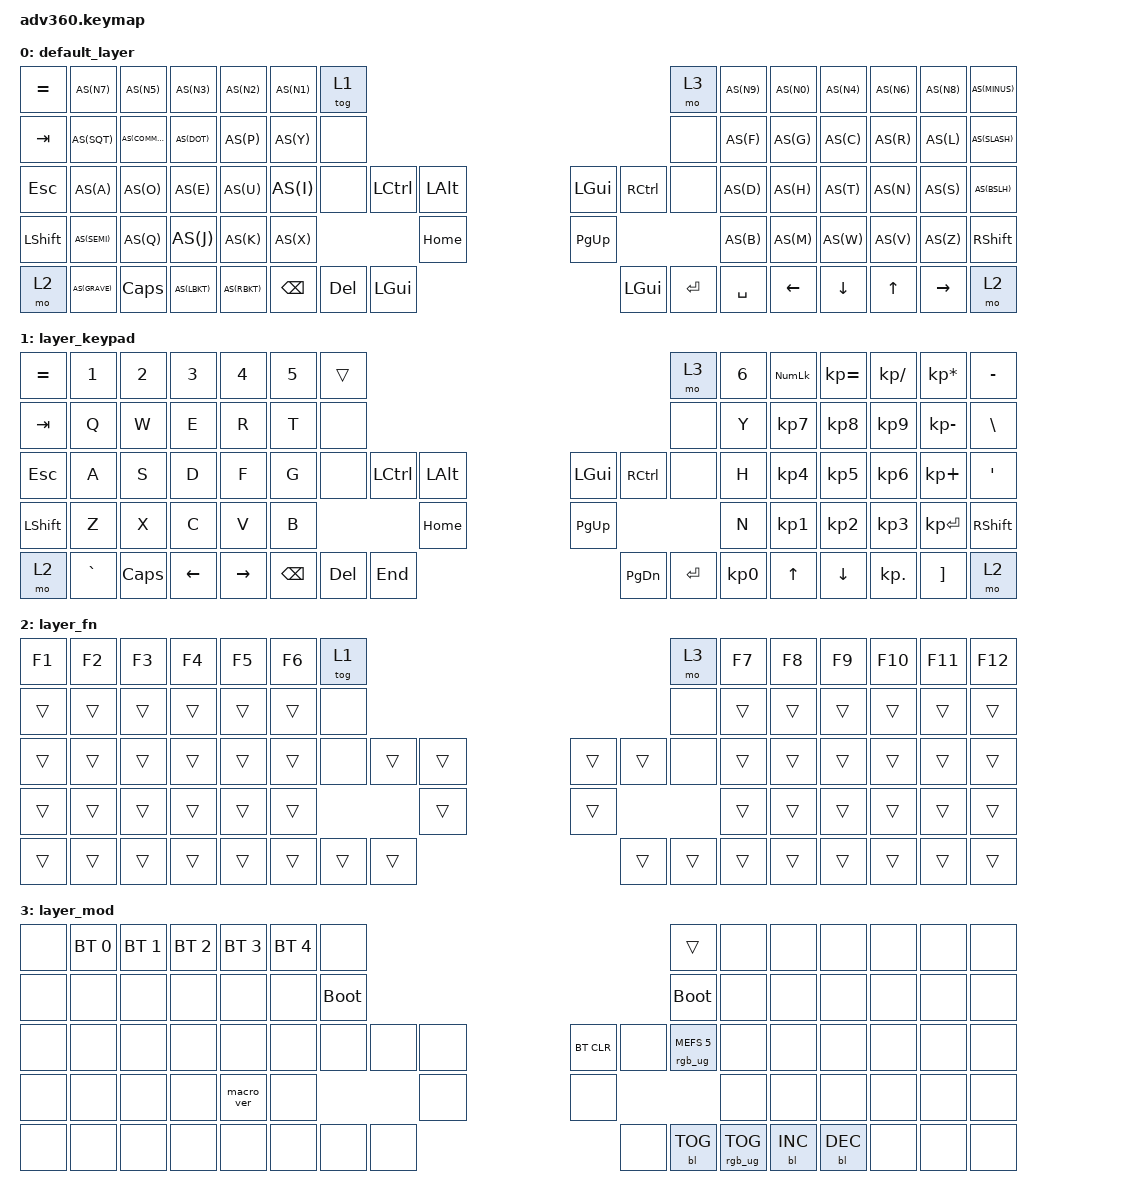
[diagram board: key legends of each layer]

/*
 * Copyright (c) 2020 The ZMK Contributors
 *
 * SPDX-License-Identifier: MIT
 */


/* THIS FILE WAS GENERATED!
 *
 * This file was generated automatically. You may or may not want to
 * edit it directly.
 */

#include <behaviors.dtsi>
#include <dt-bindings/zmk/keys.h>
#include <dt-bindings/zmk/bt.h>
#include <dt-bindings/zmk/rgb.h>
#include <dt-bindings/zmk/backlight.h>

#define AS(keycode) &as LS(keycode) keycode     // Autoshift Macro

/ {
  behaviors {
    #include "macros.dtsi"
    #include "version.dtsi"

    hm: homerow_mods {
        compatible = "zmk,behavior-hold-tap";
        label = "HOMEROW_MODS";
        #binding-cells = <2>;
        tapping-term-ms = <200>;
        quick_tap_ms = <175>;
        flavor = "tap-preferred";
        bindings = <&kp>, <&kp>;
    };

    as: auto_shift {
        compatible = "zmk,behavior-hold-tap";
        #binding-cells = <2>;
        tapping_term_ms = <250>;
        quick_tap_ms = <0>;
        flavor = "tap-preferred";
        bindings = <&kp>, <&kp>;
    };
  };

    keymap {
        compatible = "zmk,keymap";


        default_layer {
            bindings = <
 &kp EQUAL      AS(N7)     AS(N5)    AS(N3)    AS(N2)   AS(N1)             &tog 1                                                                 &mo 3   AS(N9)    AS(N0)    AS(N4)  AS(N6)     AS(N8)  AS(MINUS)
   &kp TAB     AS(SQT)  AS(COMMA)   AS(DOT)     AS(P)    AS(Y)              &none                                                                 &none    AS(F)     AS(G)     AS(C)   AS(R)      AS(L)  AS(SLASH)
   &kp ESC       AS(A)      AS(O)     AS(E)     AS(U)    AS(I)              &none  &kp LCTRL  &kp LALT                   &kp LGUI  &kp RCTRL      &none    AS(D)     AS(H)     AS(T)   AS(N)      AS(S)   AS(BSLH)
 &kp LSHFT    AS(SEMI)      AS(Q)     AS(J)     AS(K)    AS(X)                                &kp HOME                  &kp PG_UP                          AS(B)     AS(M)     AS(W)   AS(V)      AS(Z) &kp RSHFT
     &mo 2   AS(GRAVE)  &kp CAPS   AS(LBKT)  AS(RBKT)                   &kp BSPC    &kp DEL   &kp LGUI                  &kp LGUI   &kp ENTER  &kp SPACE          &kp LEFT  &kp DOWN  &kp UP  &kp RIGHT      &mo 2
            >;
        };

        layer_keypad {
            bindings = <
 &kp EQUAL     &kp N1    &kp N2    &kp N3     &kp N4  &kp N5              &trans                                                                 &mo 3  &kp N6  &kp KP_NUM  &kp KP_EQUAL  &kp KP_DIVIDE  &kp KP_MULTIPLY  &kp MINUS
   &kp TAB      &kp Q     &kp W     &kp E      &kp R   &kp T               &none                                                                 &none   &kp Y   &kp KP_N7     &kp KP_N8      &kp KP_N9     &kp KP_MINUS   &kp BSLH
   &kp ESC      &kp A     &kp S     &kp D      &kp F   &kp G               &none  &kp LCTRL  &kp LALT                   &kp LGUI  &kp RCTRL      &none   &kp H   &kp KP_N4     &kp KP_N5      &kp KP_N6      &kp KP_PLUS    &kp SQT
 &kp LSHFT      &kp Z     &kp X     &kp C      &kp V   &kp B                                 &kp HOME                  &kp PG_UP                         &kp N   &kp KP_N1     &kp KP_N2      &kp KP_N3     &kp KP_ENTER  &kp RSHFT
     &mo 2  &kp GRAVE  &kp CAPS  &kp LEFT  &kp RIGHT                    &kp BSPC    &kp DEL   &kp END                  &kp PG_DN  &kp ENTER  &kp KP_N0              &kp UP      &kp DOWN     &kp KP_DOT         &kp RBKT      &mo 2
            >;
        };

        layer_fn {
            bindings = <
 &kp F1  &kp F2  &kp F3  &kp F4  &kp F5  &kp F6            &tog 1                                                   &mo 3  &kp F7  &kp F8  &kp F9  &kp F10  &kp F11  &kp F12
 &trans  &trans  &trans  &trans  &trans  &trans             &none                                                   &none  &trans  &trans  &trans   &trans   &trans   &trans
 &trans  &trans  &trans  &trans  &trans  &trans             &none  &trans  &trans                  &trans  &trans   &none  &trans  &trans  &trans   &trans   &trans   &trans
 &trans  &trans  &trans  &trans  &trans  &trans                            &trans                  &trans                  &trans  &trans  &trans   &trans   &trans   &trans
 &trans  &trans  &trans  &trans  &trans                    &trans  &trans  &trans                  &trans  &trans  &trans          &trans  &trans   &trans   &trans   &trans
            >;
        };

        layer_mod {
            bindings = <
  &none  &bt BT_SEL 0  &bt BT_SEL 1  &bt BT_SEL 2  &bt BT_SEL 3  &bt BT_SEL 4                  &none                                                                          &trans   &none       &none       &none   &none   &none   &none
  &none         &none         &none         &none         &none         &none            &bootloader                                                                     &bootloader   &none       &none       &none   &none   &none   &none
  &none         &none         &none         &none         &none         &none                  &none   &none   &none                  &bt BT_CLR       &none  &rgb_ug RGB_MEFS_CMD 5   &none       &none       &none   &none   &none   &none
  &none         &none         &none         &none    &macro_ver         &none                                  &none                       &none                                       &none       &none       &none   &none   &none   &none
  &none         &none         &none         &none         &none                                &none   &none   &none                       &none  &bl BL_TOG         &rgb_ug RGB_TOG          &bl BL_INC  &bl BL_DEC   &none   &none   &none
            >;
        };

    };
};
